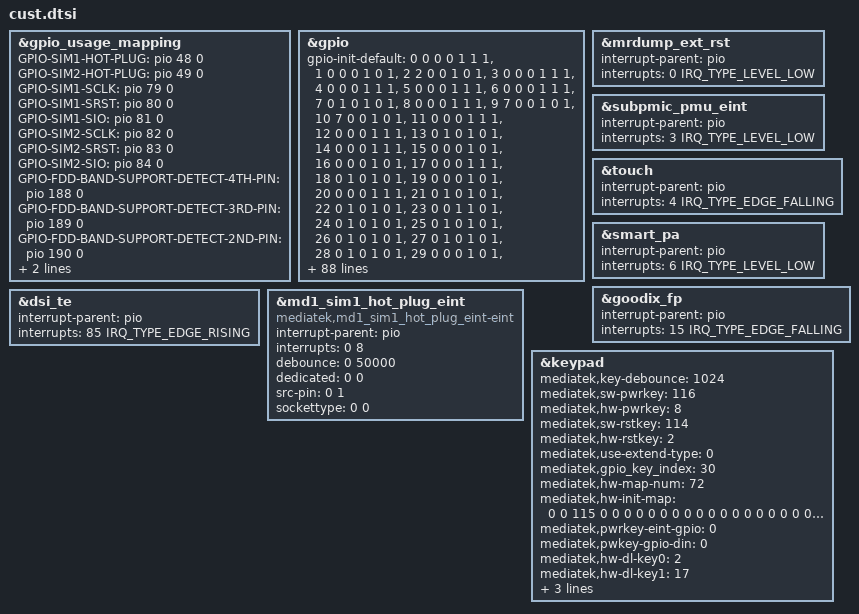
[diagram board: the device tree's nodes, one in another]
/*
 * Generated by MTK SP DrvGen Version: 3.5.160809 for MT6835_6377.
 * 2024-05-11 10:22:13
 * Do Not Modify The File.
 * Copyright Mediatek Inc. (c) 2016.
 */

/*************************
 * ADC DTSI File
 ************************/



/*************************
 * CLK_BUF DTSI File
 ************************/



/*************************
 * I2C DTSI File
 ************************/



/*************************
 * GPIO DTSI File
 ************************/

&gpio_usage_mapping {
	GPIO-SIM1-HOT-PLUG = <&pio 48 0>;
	GPIO-SIM2-HOT-PLUG = <&pio 49 0>;
	GPIO-SIM1-SCLK = <&pio 79 0>;
	GPIO-SIM1-SRST = <&pio 80 0>;
	GPIO-SIM1-SIO = <&pio 81 0>;
	GPIO-SIM2-SCLK = <&pio 82 0>;
	GPIO-SIM2-SRST = <&pio 83 0>;
	GPIO-SIM2-SIO = <&pio 84 0>;
	GPIO-FDD-BAND-SUPPORT-DETECT-4TH-PIN = <&pio 188 0>;
	GPIO-FDD-BAND-SUPPORT-DETECT-3RD-PIN = <&pio 189 0>;
	GPIO-FDD-BAND-SUPPORT-DETECT-2ND-PIN = <&pio 190 0>;
	GPIO-FDD-BAND-SUPPORT-DETECT-1ST-PIN = <&pio 191 0>;
};

&gpio{
	gpio-init-default = <0 0 0 0 1 1 1>,
		<1 0 0 0 1 0 1>,
		<2 2 0 0 1 0 1>,
		<3 0 0 0 1 1 1>,
		<4 0 0 0 1 1 1>,
		<5 0 0 0 1 1 1>,
		<6 0 0 0 1 1 1>,
		<7 0 1 0 1 0 1>,
		<8 0 0 0 1 1 1>,
		<9 7 0 0 1 0 1>,
		<10 7 0 0 1 0 1>,
		<11 0 0 0 1 1 1>,
		<12 0 0 0 1 1 1>,
		<13 0 1 0 1 0 1>,
		<14 0 0 0 1 1 1>,
		<15 0 0 0 1 0 1>,
		<16 0 0 0 1 0 1>,
		<17 0 0 0 1 1 1>,
		<18 0 1 0 1 0 1>,
		<19 0 0 0 1 0 1>,
		<20 0 0 0 1 1 1>,
		<21 0 1 0 1 0 1>,
		<22 0 1 0 1 0 1>,
		<23 0 0 1 1 0 1>,
		<24 0 1 0 1 0 1>,
		<25 0 1 0 1 0 1>,
		<26 0 1 0 1 0 1>,
		<27 0 1 0 1 0 1>,
		<28 0 1 0 1 0 1>,
		<29 0 0 0 1 0 1>,
		<30 0 0 0 1 1 1>,
		<31 1 0 0 1 1 1>,
		<32 0 1 0 1 0 1>,
		<33 7 0 0 1 0 1>,
		<34 0 1 0 1 0 1>,
		<35 0 1 0 1 0 1>,
		<36 0 0 0 1 0 0>,
		<37 0 0 0 1 0 0>,
		<38 0 0 0 1 0 0>,
		<39 1 0 0 1 0 1>,
		<40 0 0 0 1 0 0>,
		<41 0 0 0 1 0 0>,
		<42 0 0 0 1 0 0>,
		<43 0 1 0 1 0 1>,
		<44 1 0 0 0 0 1>,
		<45 1 0 0 1 0 1>,
		<46 1 0 0 0 0 1>,
		<47 3 0 0 1 0 1>,
		<48 1 0 0 1 1 1>,
		<49 1 0 0 1 1 1>,
		<50 1 0 0 0 0 1>,
		<51 1 0 0 1 1 1>,
		<52 1 0 0 0 0 1>,
		<53 1 0 0 1 1 1>,
		<54 0 1 0 1 0 1>,
		<55 7 0 0 1 0 1>,
		<56 7 0 0 1 0 1>,
		<57 7 0 0 1 0 1>,
		<58 7 0 0 0 0 1>,
		<59 7 0 0 1 0 1>,
		<60 2 0 0 1 0 1>,
		<61 2 0 0 1 1 1>,
		<62 6 0 0 1 1 1>,
		<63 6 0 0 1 1 1>,
		<64 1 0 0 1 0 1>,
		<65 1 0 0 1 1 1>,
		<66 1 0 0 1 0 1>,
		<67 1 0 0 1 0 1>,
		<68 1 0 0 0 0 0>,
		<69 1 0 0 0 0 0>,
		<70 1 0 0 0 0 0>,
		<71 1 0 0 0 0 0>,
		<73 1 0 0 0 0 1>,
		<74 1 0 0 1 1 1>,
		<75 1 0 0 1 1 1>,
		<76 1 0 0 1 1 1>,
		<77 1 0 0 1 1 1>,
		<78 1 0 0 1 1 1>,
		<79 1 0 0 0 0 1>,
		<80 1 0 0 0 0 1>,
		<81 1 0 0 1 1 1>,
		<82 1 0 0 0 0 1>,
		<83 1 0 0 0 0 1>,
		<84 1 0 0 1 1 1>,
		<85 1 0 0 1 0 1>,
		<86 0 1 0 1 0 1>,
		<87 1 0 0 0 0 1>,
		<88 1 0 0 1 0 1>,
		<89 1 0 0 1 0 1>,
		<90 1 0 0 1 0 1>,
		<91 1 0 0 1 0 1>,
		<92 1 0 0 1 1 1>,
		<93 1 0 0 1 0 1>,
		<94 1 0 0 1 0 1>,
		<95 1 0 0 0 0 1>,
		<96 1 0 0 0 0 1>,
		<97 1 0 0 0 0 1>,
		<98 1 0 0 0 0 1>,
		<99 1 0 0 0 0 1>,
		<100 1 0 0 0 0 1>,
		<101 1 0 0 0 0 1>,
		<102 1 0 0 0 0 1>,
		<103 1 0 0 0 0 1>,
		<104 1 0 0 0 0 1>,
		<105 1 0 0 0 0 1>,
		<106 1 0 0 0 0 1>,
		<107 1 0 0 0 0 1>,
		<108 1 0 0 0 0 1>,
		<109 1 0 0 0 0 1>,
		<110 1 0 0 0 0 1>,
		<111 1 0 0 0 0 1>,
		<112 1 0 0 0 0 1>,
		<113 1 0 0 0 0 1>,
		<114 1 0 0 0 0 1>,
		<115 1 0 0 0 0 1>,
		<116 1 0 0 1 0 1>,
		<117 1 0 0 0 0 1>,
		<118 1 0 0 1 0 1>,
		<119 1 0 0 0 0 1>,
		<120 1 0 0 1 0 1>,
		<121 1 0 0 0 0 1>,
		<122 1 0 0 1 0 1>,
		<123 4 0 0 1 0 1>,
		<124 0 0 0 1 1 1>,
		<125 1 0 0 1 0 1>,
		<126 1 0 0 1 0 1>,
		<127 1 0 0 1 1 1>,
		<128 1 0 0 1 1 1>,
		<129 2 0 0 1 1 1>,
		<130 2 0 0 1 1 1>,
		<131 1 0 0 1 1 1>,
		<132 1 0 0 1 1 1>,
		<133 1 0 0 1 1 1>,
		<134 1 0 0 1 1 1>,
		<135 1 0 0 1 1 1>,
		<136 1 0 0 1 1 1>,
		<137 1 0 0 1 1 1>,
		<138 1 0 0 1 1 1>,
		<139 1 0 0 1 1 1>,
		<140 1 0 0 1 1 1>,
		<141 1 0 0 1 1 1>,
		<142 1 0 0 1 1 1>,
		<143 1 0 0 1 1 1>,
		<144 1 0 0 1 1 1>,
		<145 1 0 0 1 1 1>,
		<146 1 0 0 1 1 1>,
		<147 2 0 0 1 0 1>,
		<148 0 1 0 1 0 1>,
		<149 0 1 1 1 0 1>,
		<150 0 1 0 1 0 1>,
		<151 0 0 0 1 0 1>,
		<152 1 0 0 0 0 1>,
		<153 1 0 0 0 0 1>,
		<154 1 0 0 0 0 1>,
		<155 1 0 0 0 0 1>,
		<156 1 0 0 0 0 1>,
		<157 1 0 0 0 0 1>,
		<158 1 0 0 0 0 1>,
		<159 1 0 0 1 0 1>,
		<160 1 0 0 0 0 1>,
		<161 1 0 0 0 0 1>,
		<162 1 0 0 0 0 1>,
		<163 1 0 0 0 0 1>,
		<164 1 0 0 0 0 1>,
		<165 0 0 0 1 0 1>,
		<166 1 0 0 0 0 1>,
		<167 1 0 0 0 0 1>,
		<168 1 0 0 1 0 1>,
		<169 1 0 0 1 0 1>,
		<170 1 0 0 1 0 1>,
		<171 0 0 0 0 0 1>,
		<172 0 0 0 1 0 1>,
		<173 0 0 0 1 0 1>,
		<174 0 0 0 1 0 1>,
		<175 0 0 0 1 0 1>,
		<176 0 0 0 1 0 1>,
		<177 0 0 0 1 0 1>,
		<178 0 0 0 1 0 1>,
		<179 0 0 0 1 0 1>,
		<180 0 0 0 1 0 1>,
		<181 0 0 0 1 0 1>,
		<186 0 1 0 1 0 1>,
		<188 0 0 0 1 1 1>,
		<189 0 0 0 1 1 1>,
		<190 0 0 0 1 1 1>,
		<191 0 0 0 1 1 1>,
		<193 0 0 0 1 0 0>,
		<194 0 0 0 1 0 0>,
		<195 0 0 0 1 0 0>,
		<196 0 0 0 1 0 0>,
		<197 0 0 0 1 0 0>,
		<198 0 0 0 1 0 0>,
		<199 0 0 0 1 0 0>,
		<200 0 0 0 1 0 0>,
		<201 0 0 0 1 0 0>,
		<202 0 0 0 1 0 0>,
		<203 0 0 0 1 0 0>,
		<204 0 0 0 1 0 0>,
		<205 0 0 0 1 0 0>,
		<206 0 0 0 1 0 0>,
		<207 0 0 0 1 0 0>,
		<208 0 0 0 1 0 0>,
		<209 0 0 0 1 0 0>,
		<210 0 0 0 1 0 0>,
		<211 0 0 0 1 0 0>,
		<212 0 0 0 1 0 0>;
};


/*************************
 * EINT DTSI File
 ************************/

#include <dt-bindings/interrupt-controller/irq.h>
#include <dt-bindings/interrupt-controller/arm-gic.h>

&mrdump_ext_rst {
	interrupt-parent = <&pio>;
	interrupts = <0 IRQ_TYPE_LEVEL_LOW>;
	status = "okay";
};

&subpmic_pmu_eint {
	interrupt-parent = <&pio>;
	interrupts = <3 IRQ_TYPE_LEVEL_LOW>;
	status = "okay";
};

&touch {
	interrupt-parent = <&pio>;
	interrupts = <4 IRQ_TYPE_EDGE_FALLING>;
	status = "okay";
};

&smart_pa {
	interrupt-parent = <&pio>;
	interrupts = <6 IRQ_TYPE_LEVEL_LOW>;
	status = "okay";
};

&goodix_fp {
	interrupt-parent = <&pio>;
	interrupts = <15 IRQ_TYPE_EDGE_FALLING>;
	status = "okay";
};

&dsi_te {
	interrupt-parent = <&pio>;
	interrupts = <85 IRQ_TYPE_EDGE_RISING>;
	status = "okay";
};



/*************************
 * MD1_EINT DTSI File
 ************************/

&md1_sim1_hot_plug_eint {
	compatible = "mediatek,md1_sim1_hot_plug_eint-eint";
	interrupt-parent = <&pio>;
	interrupts = <0 8>;
	debounce = <0 50000>;
	dedicated = <0 0>;
	src-pin = <0 1>;
	sockettype = <0 0>;
	status = "okay";
};



/*************************
 * PMIC DTSI File
 ************************/



/*************************
 * POWER DTSI File
 ************************/



/*************************
 * KPD DTSI File
 ************************/

&keypad {
	mediatek,key-debounce = <1024>;
	mediatek,sw-pwrkey = <116>;
	mediatek,hw-pwrkey = <8>;
	mediatek,sw-rstkey  = <114>;
	mediatek,hw-rstkey = <2>;
	mediatek,use-extend-type = <0>;
	mediatek,gpio_key_index = <30>;
	/*HW Keycode [0~71] -> Linux Keycode*/
	mediatek,hw-map-num = <72>;
	mediatek,hw-init-map = <0 0 115 0 0 0 0 0 0 0 0 0 0 0 0 0 0 0 0 0 0 0 0 0
				0 0 0 0 0 0 0 0 0 0 0 0 0 0 0 0 0 0 0 0 0 0 0 0
				0 0 0 0 0 0 0 0 0 0 0 0 0 0 0 0 0 0 0 0 0 0 0 0>;
	mediatek,pwrkey-eint-gpio = <0>;
	mediatek,pwkey-gpio-din  = <0>;
	mediatek,hw-dl-key0 = <2>;
	mediatek,hw-dl-key1 = <17>;
	mediatek,hw-dl-key2 = <8>;
	mediatek,hw-recovery-key = <2>;
	mediatek,hw-factory-key = <17>;
	status = "okay";
};


